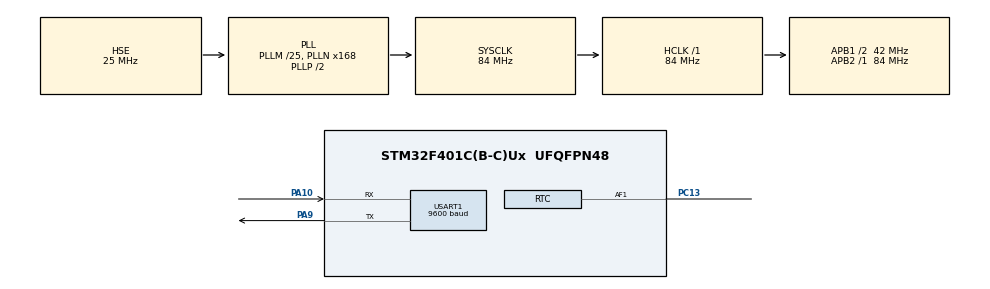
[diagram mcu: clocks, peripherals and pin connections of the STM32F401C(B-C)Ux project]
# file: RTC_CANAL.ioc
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Mcu.Family=STM32F4
Mcu.Name=STM32F401C(B-C)Ux
Mcu.Package=UFQFPN48
NVIC.PriorityGroup=NVIC_PRIORITYGROUP_4
PA10.Mode=Asynchronous
PA10.Signal=USART1_RX
PA9.Mode=Asynchronous
PA9.Signal=USART1_TX
PC13-ANTI_TAMP.Mode=Calibration_1Hz
PC13-ANTI_TAMP.Signal=RTC_AF1
PC14-OSC32_IN.Mode=LSE-External-Oscillator
PC14-OSC32_IN.Signal=RCC_OSC32_IN
PC15-OSC32_OUT.Mode=LSE-External-Oscillator
PC15-OSC32_OUT.Signal=RCC_OSC32_OUT
PH0\ -\ OSC_IN.Mode=HSE-External-Oscillator
PH0\ -\ OSC_IN.Signal=RCC_OSC_IN
PH1\ -\ OSC_OUT.Mode=HSE-External-Oscillator
PH1\ -\ OSC_OUT.Signal=RCC_OSC_OUT
ProjectManager.HeapSize=0x200
ProjectManager.StackSize=0x400
ProjectManager.TargetToolchain=STM32CubeIDE
RCC.48MHZClocksFreq_Value=42000000
RCC.AHBFreq_Value=84000000
RCC.APB1CLKDivider=RCC_HCLK_DIV2
RCC.APB1Freq_Value=42000000
RCC.APB1TimFreq_Value=84000000
RCC.APB2Freq_Value=84000000
RCC.APB2TimFreq_Value=84000000
RCC.CortexFreq_Value=84000000
RCC.HCLKFreq_Value=84000000
RCC.HSE_VALUE=25000000
RCC.HSI_VALUE=16000000
RCC.PLLM=25
RCC.PLLN=168
RCC.PLLSourceVirtual=RCC_PLLSOURCE_HSE
RCC.RCC_RTC_Clock_Source=RCC_RTCCLKSOURCE_LSE
RCC.SYSCLKFreq_VALUE=84000000
RCC.SYSCLKSource=RCC_SYSCLKSOURCE_PLLCLK
RCC.VCOOutputFreq_Value=168000000
RTC.Date=17
RTC.Format=RTC_FORMAT_BIN
RTC.Hours=10
RTC.Minutes=20
RTC.Month=RTC_MONTH_OCTOBER
RTC.Seconds=30
RTC.WeekDay=RTC_WEEKDAY_FRIDAY
RTC.Year=23
USART1.BaudRate=9600
USART1.VirtualMode=VM_ASYNC
VP_RTC_VS_RTC_Activate.Mode=RTC_Enabled
VP_RTC_VS_RTC_Calendar.Mode=RTC_Calendar
board=custom

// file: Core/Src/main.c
/* USER CODE BEGIN Header */
/**
  ******************************************************************************
  * @file           : main.c
  * @brief          : Main program body
  ******************************************************************************
  * @attention
  *
  * Copyright (c) 2024 STMicroelectronics.
  * All rights reserved.
  *
  * This software is licensed under terms that can be found in the LICENSE file
  * in the root directory of this software component.
  * If no LICENSE file comes with this software, it is provided AS-IS.
  *
  ******************************************************************************
  */
/* USER CODE END Header */
#include "main.h"

/* USER CODE BEGIN Includes */

#include "uart.h"
/* USER CODE END Includes */

RTC_HandleTypeDef hrtc;

UART_HandleTypeDef huart1;

/* USER CODE BEGIN PV */
RTC_TimeTypeDef tiempo;
RTC_DateTypeDef fecha;
char texto[50];
/* USER CODE END PV */

void SystemClock_Config(void);
static void MX_GPIO_Init(void);
static void MX_RTC_Init(void);
static void MX_USART1_UART_Init(void);

int main(void)
{

  /* MCU Configuration--------------------------------------------------------*/

  /* Reset of all peripherals, Initializes the Flash interface and the Systick. */
  HAL_Init();

  /* Configure the system clock */
  SystemClock_Config();

  /* Initialize all configured peripherals */
  MX_GPIO_Init();
  MX_RTC_Init();
  MX_USART1_UART_Init();
  /* USER CODE BEGIN 2 */
    uartx_write_text(&huart1, "INICIANDO\r\n");
  /* USER CODE END 2 */

  /* Infinite loop */
  /* USER CODE BEGIN WHILE */
  while (1)
  {
	  HAL_RTC_GetTime(&hrtc, &tiempo, RTC_FORMAT_BIN);
     HAL_RTC_GetDate(&hrtc, &fecha, RTC_FORMAT_BIN);
     sprintf(texto,"%02d:%02d:%02d  %02d/%02d/20%02d\r\n",tiempo.Hours,tiempo.Minutes,tiempo.Seconds,fecha.Date,fecha.Month,fecha.Year);
     uartx_write_text(&huart1, texto);
     HAL_Delay(950);

    /* USER CODE END WHILE */

  }
}

void SystemClock_Config(void)
{
  RCC_OscInitTypeDef RCC_OscInitStruct = {0};
  RCC_ClkInitTypeDef RCC_ClkInitStruct = {0};

  /** Configure the main internal regulator output voltage
  */
  __HAL_RCC_PWR_CLK_ENABLE();
  __HAL_PWR_VOLTAGESCALING_CONFIG(PWR_REGULATOR_VOLTAGE_SCALE2);

  /** Initializes the RCC Oscillators according to the specified parameters
  * in the RCC_OscInitTypeDef structure.
  */
  RCC_OscInitStruct.OscillatorType = RCC_OSCILLATORTYPE_HSE|RCC_OSCILLATORTYPE_LSE;
  RCC_OscInitStruct.HSEState = RCC_HSE_ON;
  RCC_OscInitStruct.LSEState = RCC_LSE_ON;
  RCC_OscInitStruct.PLL.PLLState = RCC_PLL_ON;
  RCC_OscInitStruct.PLL.PLLSource = RCC_PLLSOURCE_HSE;
  RCC_OscInitStruct.PLL.PLLM = 25;
  RCC_OscInitStruct.PLL.PLLN = 168;
  RCC_OscInitStruct.PLL.PLLP = RCC_PLLP_DIV2;
  RCC_OscInitStruct.PLL.PLLQ = 4;
  if (HAL_RCC_OscConfig(&RCC_OscInitStruct) != HAL_OK)
  {
    Error_Handler();
  }

  /** Initializes the CPU, AHB and APB buses clocks
  */
  RCC_ClkInitStruct.ClockType = RCC_CLOCKTYPE_HCLK|RCC_CLOCKTYPE_SYSCLK
                              |RCC_CLOCKTYPE_PCLK1|RCC_CLOCKTYPE_PCLK2;
  RCC_ClkInitStruct.SYSCLKSource = RCC_SYSCLKSOURCE_PLLCLK;
  RCC_ClkInitStruct.AHBCLKDivider = RCC_SYSCLK_DIV1;
  RCC_ClkInitStruct.APB1CLKDivider = RCC_HCLK_DIV2;
  RCC_ClkInitStruct.APB2CLKDivider = RCC_HCLK_DIV1;

  if (HAL_RCC_ClockConfig(&RCC_ClkInitStruct, FLASH_LATENCY_2) != HAL_OK)
  {
    Error_Handler();
  }
}

static void MX_RTC_Init(void)
{

  RTC_TimeTypeDef sTime = {0};
  RTC_DateTypeDef sDate = {0};

  /** Initialize RTC Only
  */
  hrtc.Instance = RTC;
  hrtc.Init.HourFormat = RTC_HOURFORMAT_24;
  hrtc.Init.AsynchPrediv = 127;
  hrtc.Init.SynchPrediv = 255;
  hrtc.Init.OutPut = RTC_OUTPUT_DISABLE;
  hrtc.Init.OutPutPolarity = RTC_OUTPUT_POLARITY_HIGH;
  hrtc.Init.OutPutType = RTC_OUTPUT_TYPE_OPENDRAIN;
  if (HAL_RTC_Init(&hrtc) != HAL_OK)
  {
    Error_Handler();
  }

  /* USER CODE BEGIN Check_RTC_BKUP */
  // Incluir código para verificar si se ha guardado el dato en el registro de respaldo
      if (HAL_RTCEx_BKUPRead(&hrtc, RTC_BKP_DR0) == 0x1017)
      {
        // Si se ha guardado el dato en el registro de respaldo,
        // recuperar la hora y la fecha del RTC y no volver a inicializar
        HAL_RTC_GetDate(&hrtc, &sDate, RTC_FORMAT_BIN);
        HAL_RTC_GetTime(&hrtc, &sTime, RTC_FORMAT_BIN);
        return;

      }
      HAL_RTCEx_BKUPWrite(&hrtc, RTC_BKP_DR0, 0x1017);

  /* USER CODE END Check_RTC_BKUP */

  /** Initialize RTC and set the Time and Date
  */
  sTime.Hours = 10;
  sTime.Minutes = 20;
  sTime.Seconds = 30;
  sTime.DayLightSaving = RTC_DAYLIGHTSAVING_NONE;
  sTime.StoreOperation = RTC_STOREOPERATION_RESET;
  if (HAL_RTC_SetTime(&hrtc, &sTime, RTC_FORMAT_BIN) != HAL_OK)
  {
    Error_Handler();
  }
  sDate.WeekDay = RTC_WEEKDAY_FRIDAY;
  sDate.Month = RTC_MONTH_OCTOBER;
  sDate.Date = 17;
  sDate.Year = 23;

  if (HAL_RTC_SetDate(&hrtc, &sDate, RTC_FORMAT_BIN) != HAL_OK)
  {
    Error_Handler();
  }

  /** Enable Calibrartion
  */
  if (HAL_RTCEx_SetCalibrationOutPut(&hrtc, RTC_CALIBOUTPUT_1HZ) != HAL_OK)
  {
    Error_Handler();
  }

}

static void MX_USART1_UART_Init(void)
{

  huart1.Instance = USART1;
  huart1.Init.BaudRate = 9600;
  huart1.Init.WordLength = UART_WORDLENGTH_8B;
  huart1.Init.StopBits = UART_STOPBITS_1;
  huart1.Init.Parity = UART_PARITY_NONE;
  huart1.Init.Mode = UART_MODE_TX_RX;
  huart1.Init.HwFlowCtl = UART_HWCONTROL_NONE;
  huart1.Init.OverSampling = UART_OVERSAMPLING_16;
  if (HAL_UART_Init(&huart1) != HAL_OK)
  {
    Error_Handler();
  }

}

static void MX_GPIO_Init(void)
{

  /* GPIO Ports Clock Enable */
  __HAL_RCC_GPIOC_CLK_ENABLE();
  __HAL_RCC_GPIOH_CLK_ENABLE();
  __HAL_RCC_GPIOA_CLK_ENABLE();

}

void Error_Handler(void)
{
  __disable_irq();
  while (1)
  {
  }
}
